# GD32G5x3 register map
File version: 1.0
CPU: CM33 r2p1, little endian, MPU, FPU, 4 interrupt priority bits
Registers are 32-bit, read-write, reset 0x0 unless marked. A register's access mark holds for its fields unless they carry their own. Offsets are from the block's base; [hi:lo] are bit positions.

## FMC — Flash memory controller
Base 0x40022000
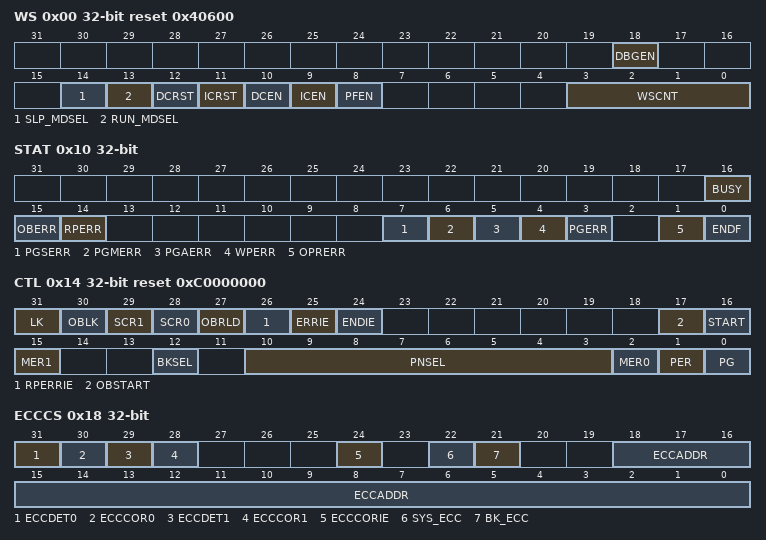
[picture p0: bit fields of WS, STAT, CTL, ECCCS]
0x00 WS reset 0x40600 — Wait state register
  [18] DBGEN — This bit is used to enable/disable the debugger by software
  [14] SLP_MDSEL — Flash power-down mode during sleep mode
  [13] RUN_MDSEL — Flash power-down mode during run mode
  [12] DCRST — Data cache reset
  [11] ICRST — Instruction cache reset
  [10] DCEN — Data cache enable
  [9] ICEN — Instruction cache enable
  [8] PFEN — Pre-fetch enable
  [3:0] WSCNT — Wait state counter register
0x04 RUNKEY wo — Unlock flash mode during run mode key register
  [31:0] RUN_KEY — RUN_MDSEL unlock register
0x08 KEY wo — Unlock key register
  [31:0] KEY — FMC_CTL unlock register
0x0C OBKEY wo — Option byte unlock key register
  [31:0] OBKEY — FMC_CTL option bytes operation unlock register
0x10 STAT access per field — Status register
  [16] BUSY ro — The flash is busy bit
  [15] OBERR rw — Option byte read error bit
  [14] RPERR rw — Read protection error flag bit
  [7] PGSERR rw — Program sequence error flag bit
  [6] PGMERR rw — Program size not match error flag bit
  [5] PGAERR rw — Program alignment error flag bit
  [4] WPERR rw — Erase / program protection error flag bit
  [3] PGERR rw — Program error flag bit
  [1] OPRERR rw — Operation error flag bit
  [0] ENDF rw — End of operation flag bit
0x14 CTL reset 0xC0000000 — Control register
  [31] LK — FMC_CTL lock bit
  [30] OBLK — FMC_OBCTL lock bit
  [29] SCR1 — Bank1 secure user area enable bit
  [28] SCR0 — Bank0 secure user area enable bit
  [27] OBRLD — Option byte reload bit
  [26] RPERRIE — Read protection error interrupt enable bit
  [25] ERRIE — OPRERR error interrupt enable bit
  [24] ENDIE — End of operation interrupt enable bit
  [17] OBSTART — Send option byte change command to FMC bit
  [16] START — Send erase command to FMC bit
  [15] MER1 — Main flash mass erase for bank1 command bit
  [12] BKSEL — Bank number selection for page erase
  [10:3] PNSEL — Page number selection
  [2] MER0 — Main flash mass erase for bank0 command bit
  [1] PER — Main flash page erase command bit
  [0] PG — Main flash page program command bit
0x18 ECCCS access per field — ECC control and status register
  [31] ECCDET0 rw — Two bit errors detected flag
  [30] ECCCOR0 rw — One-bit error detected and corrected flag
  [29] ECCDET1 rw — Two bit errors detected flag
  [28] ECCCOR1 rw — One-bit error detected and corrected flag
  [24] ECCCORIE rw — One-bit error correction interrupt enable
  [22] SYS_ECC ro — If an ECC error correction or double ECC error is detected in bootloader, this bit will be set
  [21] BK_ECC ro — ECC fail bank
  [18:0] ECCADDR ro — ECC fail address
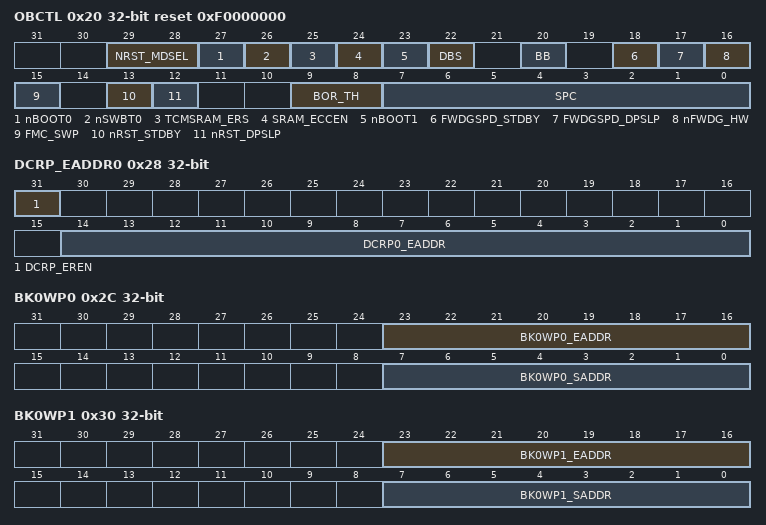
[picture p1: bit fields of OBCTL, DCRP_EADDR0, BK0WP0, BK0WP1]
0x20 OBCTL reset 0xF0000000 — Option byte control register
  [29:28] NRST_MDSEL — NRST pin mode selection
  [27] nBOOT0 — BOOT0 option bit
  [26] nSWBT0 — Software BOOT0 disable
  [25] TCMSRAM_ERS — TCM SRAM erase if system reset
  [24] SRAM_ECCEN — SRAM and TCM SRAM ECC disable
  [23] nBOOT1 — Boot1 configuration bit
  [22] DBS — Double banks or single bank selection
  [20] BB — Option byte boot bank value
  [18] FWDGSPD_STDBY — FWDGT suspend option in standby mode configuration bit
  [17] FWDGSPD_DPSLP — FWDGT suspend option in deepsleep mode configuration bit
  [16] nFWDG_HW — Free watchdog configuration bit
  [15] FMC_SWP — FMC memory mapping swap
  [13] nRST_STDBY — Option byte standby reset value
  [12] nRST_DPSLP — Option byte deepsleep reset value
  [9:8] BOR_TH — BOR threshold status bits
  [7:0] SPC — Security protection level option byte status bits
0x24 DCRP_SADDR0 reset 0xFFFF0000 — DCRP start address register 0
  [14:0] DCRP0_SADDR — DCRP area start address offset configuration bits for bank0
0x28 DCRP_EADDR0 — DCRP end address register 0
  [31] DCRP_EREN — DCRP area erase enable configuration bit
  [14:0] DCRP0_EADDR — DCRP area end address offset configuration bits for bank0
0x2C BK0WP0 — Bank0 erase/program protection area 0 register
  [23:16] BK0WP0_EADDR — WP first area end offset
  [7:0] BK0WP0_SADDR — WP first area start offset
0x30 BK0WP1 — Bank0 erase/program protection area 1 register
  [23:16] BK0WP1_EADDR — WP second area end offset
  [7:0] BK0WP1_SADDR — WP second area start offset
0x44 DCRP_SADDR1 reset 0xFFFF0000 — DCRP start address register 1
  [14:0] DCRP1_SADDR — DCRP area start address offset configuration bits for bank1
0x48 DCRP_EADDR1 — DCRP end address register 1
  [14:0] DCRP1_EAREA — DCRP area end address offset configuration bits for bank1
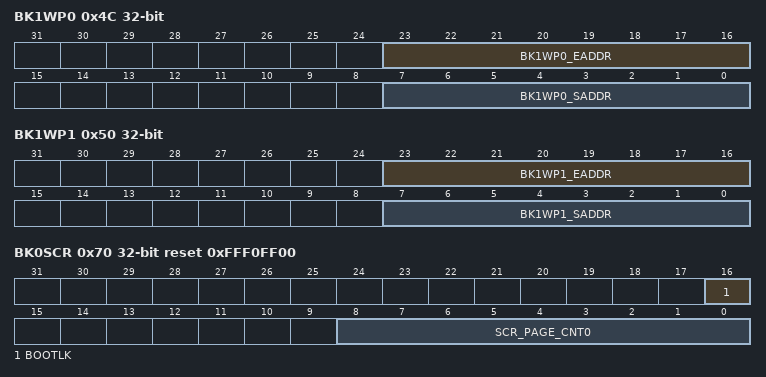
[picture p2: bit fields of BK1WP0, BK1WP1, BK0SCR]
0x4C BK1WP0 — Bank1 erase/program protection area 0 register
  [23:16] BK1WP0_EADDR — WP third area end offset
  [7:0] BK1WP0_SADDR — WP third area start offset
0x50 BK1WP1 — Bank1 erase/program protection area 1 register
  [23:16] BK1WP1_EADDR — WP fourth area end offset
  [7:0] BK1WP1_SADDR — WP fourth area start offset
0x70 BK0SCR reset 0xFFF0FF00 — Bank0 secure user area register
  [16] BOOTLK — This bit is set to force boot from user flash area
  [8:0] SCR_PAGE_CNT0 — Configure the number of pages in the bank0 secure user area
0x74 BK1SCR reset 0xFFFFFF00 — Bank1 secure user area register
  [8:0] SCR_PAGE_CNT1 — Configure the number of pages in the bank1 secure user area
0x100 PID ro — Product ID register
  [31:0] PID — Product reserved ID code register
